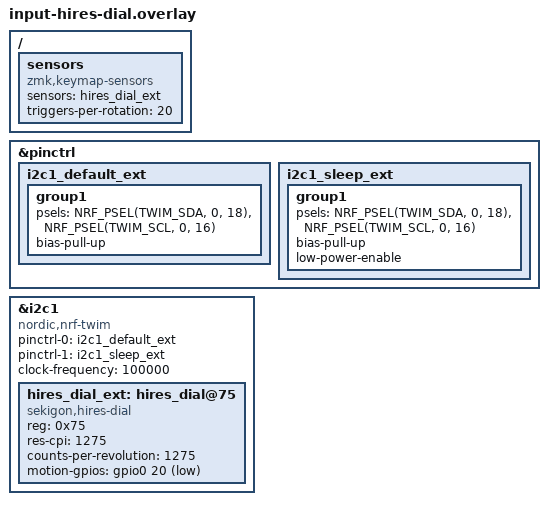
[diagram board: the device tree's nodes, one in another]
/* メイン基板のFFCコネクタにダイヤルモジュールを接続する設定 */
/* SPI0とのリソース競合を避けるため、I2C1としてハードウェアを定義します */

&pinctrl {
    /* メイン基板FFCコネクタのI2Cピン（P0.18, P0.16）をI2C1として再定義 */
    i2c1_default_ext: i2c1_default_ext {
        group1 {
            psels = <NRF_PSEL(TWIM_SDA, 0, 18)>,
                    <NRF_PSEL(TWIM_SCL, 0, 16)>;
            bias-pull-up;
        };
    };
    i2c1_sleep_ext: i2c1_sleep_ext {
        group1 {
            psels = <NRF_PSEL(TWIM_SDA, 0, 18)>,
                    <NRF_PSEL(TWIM_SCL, 0, 16)>;
            bias-pull-up;
            low-power-enable;
        };
    };
};

&i2c1 {
    status = "okay";
    compatible = "nordic,nrf-twim";
    pinctrl-0 = <&i2c1_default_ext>;
    pinctrl-1 = <&i2c1_sleep_ext>;
    pinctrl-names = "default", "sleep";
    clock-frequency = <100000>;
    
    hires_dial_ext: hires_dial@75 {
        compatible = "sekigon,hires-dial";
        reg = <0x75>;
        res-cpi = <1275>;
        counts-per-revolution = <1275>;
        /* メイン基板FFCコネクタの標準割り込みピン（トラックパッドと共通） */
        motion-gpios = <&gpio0 20 (GPIO_ACTIVE_LOW | GPIO_PULL_UP)>;
    };
};

/ {
    sensors: sensors {
        compatible = "zmk,keymap-sensors";
        sensors = <&hires_dial_ext>;
        triggers-per-rotation = <20>;
    };
};
